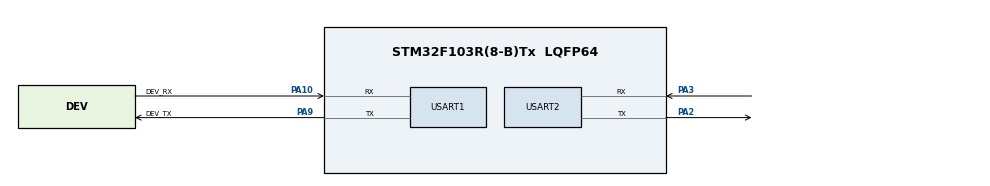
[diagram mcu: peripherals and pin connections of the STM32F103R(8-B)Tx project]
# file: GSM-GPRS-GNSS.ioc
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Dma.Request0=USART1_RX
Dma.Request1=USART2_RX
Dma.USART1_RX.0.Direction=DMA_PERIPH_TO_MEMORY
Dma.USART1_RX.0.Instance=DMA1_Channel5
Dma.USART1_RX.0.MemDataAlignment=DMA_MDATAALIGN_BYTE
Dma.USART1_RX.0.MemInc=DMA_MINC_ENABLE
Dma.USART1_RX.0.Mode=DMA_NORMAL
Dma.USART1_RX.0.PeriphDataAlignment=DMA_PDATAALIGN_BYTE
Dma.USART1_RX.0.PeriphInc=DMA_PINC_DISABLE
Dma.USART1_RX.0.Priority=DMA_PRIORITY_LOW
Dma.USART2_RX.1.Direction=DMA_PERIPH_TO_MEMORY
Dma.USART2_RX.1.Instance=DMA1_Channel6
Dma.USART2_RX.1.MemDataAlignment=DMA_MDATAALIGN_BYTE
Dma.USART2_RX.1.MemInc=DMA_MINC_ENABLE
Dma.USART2_RX.1.Mode=DMA_NORMAL
Dma.USART2_RX.1.PeriphDataAlignment=DMA_PDATAALIGN_BYTE
Dma.USART2_RX.1.PeriphInc=DMA_PINC_DISABLE
Dma.USART2_RX.1.Priority=DMA_PRIORITY_LOW
Mcu.Family=STM32F1
Mcu.Name=STM32F103R(8-B)Tx
Mcu.Package=LQFP64
NVIC.DMA1_Channel5_IRQn=true\:0\:0\:false\:false\:true
NVIC.DMA1_Channel6_IRQn=true\:0\:0\:false\:false\:true
NVIC.PriorityGroup=NVIC_PRIORITYGROUP_4
NVIC.USART1_IRQn=true\:0\:0\:false\:false\:true
NVIC.USART2_IRQn=true\:0\:0\:false\:false\:true
PA10.GPIO_Label=DEV_RX
PA10.Mode=Asynchronous
PA10.Signal=USART1_RX
PA13.Mode=Serial_Wire
PA13.Signal=SYS_JTMS-SWDIO
PA14.Mode=Serial_Wire
PA14.Signal=SYS_JTCK-SWCLK
PA2.Mode=Asynchronous
PA2.Signal=USART2_TX
PA3.Mode=Asynchronous
PA3.Signal=USART2_RX
PA9.GPIO_Label=DEV_TX
PA9.Mode=Asynchronous
PA9.Signal=USART1_TX
PD0-OSC_IN.Mode=HSE-External-Oscillator
PD0-OSC_IN.Signal=RCC_OSC_IN
PD1-OSC_OUT.Mode=HSE-External-Oscillator
PD1-OSC_OUT.Signal=RCC_OSC_OUT
ProjectManager.HeapSize=0x200
ProjectManager.StackSize=0x400
ProjectManager.TargetToolchain=MDK-ARM V5
RCC.APB1Freq_Value=8000000
RCC.APB2Freq_Value=8000000
board=GSM-GPRS-GNSS

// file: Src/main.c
/**
  ******************************************************************************
  * File Name          : main.c
  * Description        : Main program body
  ******************************************************************************
  *
  * COPYRIGHT(c) 2017 STMicroelectronics
  *
  * Redistribution and use in source and binary forms, with or without modification,
  * are permitted provided that the following conditions are met:
  *   1. Redistributions of source code must retain the above copyright notice,
  *      this list of conditions and the following disclaimer.
  *   2. Redistributions in binary form must reproduce the above copyright notice,
  *      this list of conditions and the following disclaimer in the documentation
  *      and/or other materials provided with the distribution.
  *   3. Neither the name of STMicroelectronics nor the names of its contributors
  *      may be used to endorse or promote products derived from this software
  *      without specific prior written permission.
  *
  * THIS SOFTWARE IS PROVIDED BY THE COPYRIGHT HOLDERS AND CONTRIBUTORS "AS IS"
  * AND ANY EXPRESS OR IMPLIED WARRANTIES, INCLUDING, BUT NOT LIMITED TO, THE
  * IMPLIED WARRANTIES OF MERCHANTABILITY AND FITNESS FOR A PARTICULAR PURPOSE ARE
  * DISCLAIMED. IN NO EVENT SHALL THE COPYRIGHT HOLDER OR CONTRIBUTORS BE LIABLE
  * FOR ANY DIRECT, INDIRECT, INCIDENTAL, SPECIAL, EXEMPLARY, OR CONSEQUENTIAL
  * DAMAGES (INCLUDING, BUT NOT LIMITED TO, PROCUREMENT OF SUBSTITUTE GOODS OR
  * SERVICES; LOSS OF USE, DATA, OR PROFITS; OR BUSINESS INTERRUPTION) HOWEVER
  * CAUSED AND ON ANY THEORY OF LIABILITY, WHETHER IN CONTRACT, STRICT LIABILITY,
  * OR TORT (INCLUDING NEGLIGENCE OR OTHERWISE) ARISING IN ANY WAY OUT OF THE USE
  * OF THIS SOFTWARE, EVEN IF ADVISED OF THE POSSIBILITY OF SUCH DAMAGE.
  *
  ******************************************************************************
  */
#include "main.h"
#include "stm32f1xx_hal.h"
#include "dma.h"
#include "usart.h"
#include "gpio.h"

/* USER CODE BEGIN Includes */
#include "stdio.h"
#include "string.h"

/* USER CODE END Includes */

/* USER CODE BEGIN PV */
/* Private variables ---------------------------------------------------------*/

uint8_t RxBuff[255];
uint8_t Rxflag = 0,RxByte;
uint8_t RxCount = 0;

/* USER CODE END PV */

void SystemClock_Config(void);
void Error_Handler(void);

/* USER CODE BEGIN PFP */
/* Private function prototypes -----------------------------------------------*/

/* USER CODE END PFP */

int main(void)
{

  /* USER CODE BEGIN 1 */
	char *W_Buf[5] = {"AT+CGNSPWR=1\r\n", "AT+CGNSSEQ=\"RMC\"\r\n", "AT+CGNSINF\r\n", "AT+CGNSURC=2\r\n","AT+CGNSTST=1\r\n"};
  /* USER CODE END 1 */

  /* MCU Configuration----------------------------------------------------------*/

  /* Reset of all peripherals, Initializes the Flash interface and the Systick. */
  HAL_Init();

  /* Configure the system clock */
  SystemClock_Config();

  /* Initialize all configured peripherals */
  MX_GPIO_Init();
  MX_DMA_Init();
  MX_USART1_UART_Init();
  MX_USART2_UART_Init();

  /* USER CODE BEGIN 2 */

	printf("this is a gps test\r\n");
	for(int i = 0; i <= 5; i ++ ){
		//printf("%s\r\n",W_Buf[i]);
		HAL_UART_Transmit_IT(&huart1, (uint8_t *)W_Buf[i], strlen(W_Buf[i]));	//uart1 to module

		HAL_Delay(50);

		HAL_UART_Receive_DMA(&huart1, UsartType.RX_pData, RX_LEN);
		printf("%s\r\n",UsartType.RX_pData);
		__HAL_UART_ENABLE_IT(&huart1, UART_IT_IDLE);
		HAL_Delay(500);

	}

  /* USER CODE END 2 */

  /* Infinite loop */
  while (1)
  {

  }

}

/** System Clock Configuration
*/
void SystemClock_Config(void)
{

  RCC_OscInitTypeDef RCC_OscInitStruct;
  RCC_ClkInitTypeDef RCC_ClkInitStruct;

    /**Initializes the CPU, AHB and APB busses clocks
    */
  RCC_OscInitStruct.OscillatorType = RCC_OSCILLATORTYPE_HSI;
  RCC_OscInitStruct.HSIState = RCC_HSI_ON;
  RCC_OscInitStruct.HSICalibrationValue = 16;
  RCC_OscInitStruct.PLL.PLLState = RCC_PLL_NONE;
  if (HAL_RCC_OscConfig(&RCC_OscInitStruct) != HAL_OK)
  {
    Error_Handler();
  }

    /**Initializes the CPU, AHB and APB busses clocks
    */
  RCC_ClkInitStruct.ClockType = RCC_CLOCKTYPE_HCLK|RCC_CLOCKTYPE_SYSCLK
                              |RCC_CLOCKTYPE_PCLK1|RCC_CLOCKTYPE_PCLK2;
  RCC_ClkInitStruct.SYSCLKSource = RCC_SYSCLKSOURCE_HSI;
  RCC_ClkInitStruct.AHBCLKDivider = RCC_SYSCLK_DIV1;
  RCC_ClkInitStruct.APB1CLKDivider = RCC_HCLK_DIV1;
  RCC_ClkInitStruct.APB2CLKDivider = RCC_HCLK_DIV1;

  if (HAL_RCC_ClockConfig(&RCC_ClkInitStruct, FLASH_LATENCY_0) != HAL_OK)
  {
    Error_Handler();
  }

    /**Configure the Systick interrupt time
    */
  HAL_SYSTICK_Config(HAL_RCC_GetHCLKFreq()/1000);

    /**Configure the Systick
    */
  HAL_SYSTICK_CLKSourceConfig(SYSTICK_CLKSOURCE_HCLK);

  /* SysTick_IRQn interrupt configuration */
  HAL_NVIC_SetPriority(SysTick_IRQn, 0, 0);
}

void Error_Handler(void)
{
  while(1)
  {
  }
}

/************************ (C) COPYRIGHT STMicroelectronics *****END OF FILE****/
